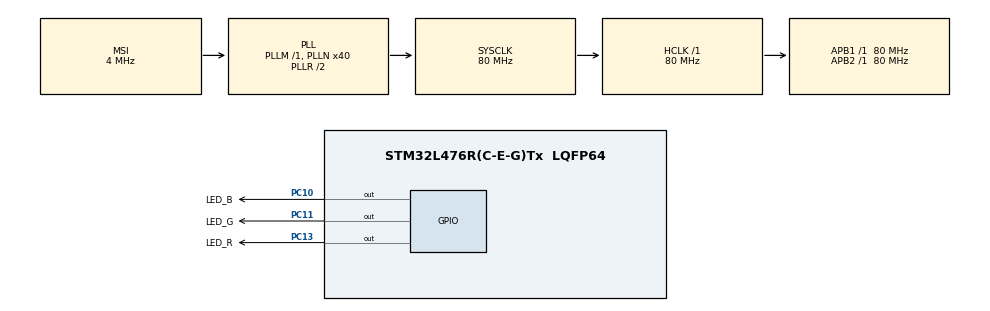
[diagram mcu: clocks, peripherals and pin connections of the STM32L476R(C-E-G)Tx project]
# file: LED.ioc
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Mcu.Family=STM32L4
Mcu.Name=STM32L476R(C-E-G)Tx
Mcu.Package=LQFP64
NVIC.PriorityGroup=NVIC_PRIORITYGROUP_4
PA13\ (JTMS-SWDIO).Mode=Serial_Wire
PA13\ (JTMS-SWDIO).Signal=SYS_JTMS-SWDIO
PA14\ (JTCK-SWCLK).Mode=Serial_Wire
PA14\ (JTCK-SWCLK).Signal=SYS_JTCK-SWCLK
PC10.GPIO_Label=LED_B
PC10.PinState=GPIO_PIN_SET
PC10.Signal=GPIO_Output
PC11.GPIO_Label=LED_G
PC11.PinState=GPIO_PIN_SET
PC11.Signal=GPIO_Output
PC13.GPIO_Label=LED_R
PC13.PinState=GPIO_PIN_SET
PC13.Signal=GPIO_Output
PC14-OSC32_IN\ (PC14).Mode=LSE-External-Oscillator
PC14-OSC32_IN\ (PC14).Signal=RCC_OSC32_IN
PC15-OSC32_OUT\ (PC15).Mode=LSE-External-Oscillator
PC15-OSC32_OUT\ (PC15).Signal=RCC_OSC32_OUT
PH0-OSC_IN\ (PH0).Mode=HSE-External-Oscillator
PH0-OSC_IN\ (PH0).Signal=RCC_OSC_IN
PH1-OSC_OUT\ (PH1).Mode=HSE-External-Oscillator
PH1-OSC_OUT\ (PH1).Signal=RCC_OSC_OUT
ProjectManager.HeapSize=0x200
ProjectManager.StackSize=0x400
ProjectManager.TargetToolchain=MDK-ARM V5.27
RCC.AHBFreq_Value=80000000
RCC.APB1Freq_Value=80000000
RCC.APB1TimFreq_Value=80000000
RCC.APB2Freq_Value=80000000
RCC.APB2TimFreq_Value=80000000
RCC.CortexFreq_Value=80000000
RCC.HCLKFreq_Value=80000000
RCC.HSE_VALUE=8000000
RCC.HSI_VALUE=16000000
RCC.MSIAutoCalibration=DISABLED
RCC.MSI_VALUE=4000000
RCC.PLLN=40
RCC.SYSCLKFreq_VALUE=80000000
RCC.SYSCLKSource=RCC_SYSCLKSOURCE_PLLCLK
RCC.VCOOutputFreq_Value=160000000
board=custom

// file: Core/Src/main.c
/* USER CODE BEGIN Header */
/**
  ******************************************************************************
  * @brief          : 跑马灯
  * @author         : OpticalMoe
  * @version        : 1.0
  * @date           : 2021.03.10
  ******************************************************************************
  * @note
  *
  * https://github.com/OpticalMoe/
  *
  ******************************************************************************
  */

/**
  * LED_R -> C.13;  LED_G -> C.11;  LED_B -> C10;
  *
  * LED正极连接 3.3V，负极连接GPIO,
  * GPIO 输出高电平时，LED熄灭；GPIO 输出低电平时，LED 点亮。
  *
  */

/* USER CODE END Header */
#include "main.h"
#include "gpio.h"

void SystemClock_Config(void);

int main(void)
{

  /* MCU Configuration--------------------------------------------------------*/

  /* Reset of all peripherals, Initializes the Flash interface and the Systick. */
  HAL_Init();

  /* Configure the system clock */
  SystemClock_Config();

  /* Initialize all configured peripherals */
  MX_GPIO_Init();

  /* Infinite loop */
  /* USER CODE BEGIN WHILE */
  while (1)
  {
    //红灯 亮
    HAL_GPIO_WritePin(LED_R_GPIO_Port, LED_R_Pin, GPIO_PIN_RESET);
    HAL_GPIO_WritePin(LED_G_GPIO_Port, LED_G_Pin, GPIO_PIN_SET);
    HAL_GPIO_WritePin(LED_B_GPIO_Port, LED_B_Pin, GPIO_PIN_SET);
    HAL_Delay(200);

    //绿灯 亮
    HAL_GPIO_WritePin(LED_R_GPIO_Port, LED_R_Pin, GPIO_PIN_SET);
    HAL_GPIO_WritePin(LED_G_GPIO_Port, LED_G_Pin, GPIO_PIN_RESET);
    HAL_GPIO_WritePin(LED_B_GPIO_Port, LED_B_Pin, GPIO_PIN_SET);
    HAL_Delay(200);

    //蓝灯 亮
    HAL_GPIO_WritePin(LED_R_GPIO_Port, LED_R_Pin, GPIO_PIN_SET);
    HAL_GPIO_WritePin(LED_G_GPIO_Port, LED_G_Pin, GPIO_PIN_SET);
    HAL_GPIO_WritePin(LED_B_GPIO_Port, LED_B_Pin, GPIO_PIN_RESET);
    HAL_Delay(200);

    //所有LED熄灭
    HAL_GPIO_WritePin(LED_R_GPIO_Port, LED_R_Pin, GPIO_PIN_SET);
    HAL_GPIO_WritePin(LED_G_GPIO_Port, LED_G_Pin, GPIO_PIN_SET);
    HAL_GPIO_WritePin(LED_B_GPIO_Port, LED_B_Pin, GPIO_PIN_SET);
    HAL_Delay(300);

    /* USER CODE END WHILE */

  }
}

void SystemClock_Config(void)
{
  RCC_OscInitTypeDef RCC_OscInitStruct = {0};
  RCC_ClkInitTypeDef RCC_ClkInitStruct = {0};

  /** Initializes the RCC Oscillators according to the specified parameters
  * in the RCC_OscInitTypeDef structure.
  */
  RCC_OscInitStruct.OscillatorType = RCC_OSCILLATORTYPE_MSI;
  RCC_OscInitStruct.MSIState = RCC_MSI_ON;
  RCC_OscInitStruct.MSICalibrationValue = 0;
  RCC_OscInitStruct.MSIClockRange = RCC_MSIRANGE_6;
  RCC_OscInitStruct.PLL.PLLState = RCC_PLL_ON;
  RCC_OscInitStruct.PLL.PLLSource = RCC_PLLSOURCE_MSI;
  RCC_OscInitStruct.PLL.PLLM = 1;
  RCC_OscInitStruct.PLL.PLLN = 40;
  RCC_OscInitStruct.PLL.PLLP = RCC_PLLP_DIV7;
  RCC_OscInitStruct.PLL.PLLQ = RCC_PLLQ_DIV2;
  RCC_OscInitStruct.PLL.PLLR = RCC_PLLR_DIV2;
  if (HAL_RCC_OscConfig(&RCC_OscInitStruct) != HAL_OK)
  {
    Error_Handler();
  }
  /** Initializes the CPU, AHB and APB buses clocks
  */
  RCC_ClkInitStruct.ClockType = RCC_CLOCKTYPE_HCLK|RCC_CLOCKTYPE_SYSCLK
                              |RCC_CLOCKTYPE_PCLK1|RCC_CLOCKTYPE_PCLK2;
  RCC_ClkInitStruct.SYSCLKSource = RCC_SYSCLKSOURCE_PLLCLK;
  RCC_ClkInitStruct.AHBCLKDivider = RCC_SYSCLK_DIV1;
  RCC_ClkInitStruct.APB1CLKDivider = RCC_HCLK_DIV1;
  RCC_ClkInitStruct.APB2CLKDivider = RCC_HCLK_DIV1;

  if (HAL_RCC_ClockConfig(&RCC_ClkInitStruct, FLASH_LATENCY_4) != HAL_OK)
  {
    Error_Handler();
  }
  /** Configure the main internal regulator output voltage
  */
  if (HAL_PWREx_ControlVoltageScaling(PWR_REGULATOR_VOLTAGE_SCALE1) != HAL_OK)
  {
    Error_Handler();
  }
}

void Error_Handler(void)
{
  __disable_irq();
  while (1)
  {
  }
}

/************************ (C) COPYRIGHT STMicroelectronics *****END OF FILE****/
